# STM32F410Rx register map
File version: 1.0
Registers are 32-bit, read-write, reset 0x0 unless marked. A register's access mark holds for its fields unless they carry their own. Offsets are from the block's base; [hi:lo] are bit positions.

## FMPI2C1 — Inter-integrated Circuit Interface
Base 0x40006000
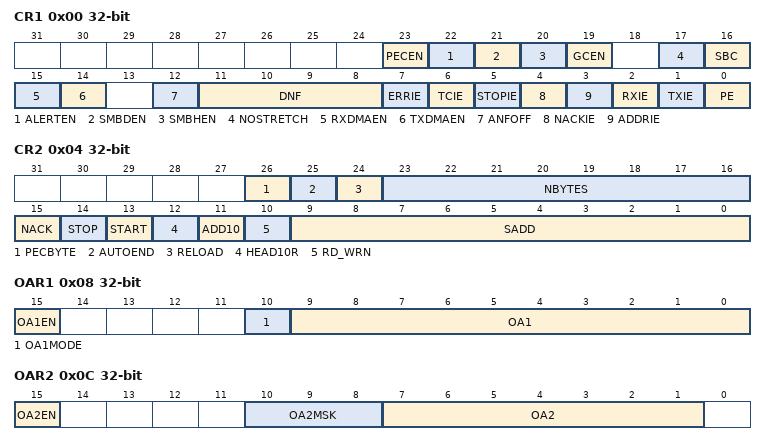
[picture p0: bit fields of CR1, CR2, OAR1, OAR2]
0x00 CR1 — FMPI2C Control register 1
  [23] PECEN — PEC enable
  [22] ALERTEN — SMBus alert enable
  [21] SMBDEN — SMBus device default address enable
  [20] SMBHEN — SMBus host address enable
  [19] GCEN — General call enable
  [17] NOSTRETCH — Clock stretching disable
  [16] SBC — Slave byte control
  [15] RXDMAEN — DMA reception requests enable
  [14] TXDMAEN — DMA transmission requests enable
  [12] ANFOFF — Analog noise filter OFF
  [11:8] DNF — Digital noise filter
  [7] ERRIE — Errors interrupt enable
  [6] TCIE — Transfer complete interrupt enable
  [5] STOPIE — STOP detection interrupt enable
  [4] NACKIE — NACK received interrupt enable
  [3] ADDRIE — Address match interrupt enable
  [2] RXIE — RX interrupt enable
  [1] TXIE — TX interrupt enable
  [0] PE — Peripheral enable
0x04 CR2 — FMPI2C Control register 2
  [26] PECBYTE — Packet error checking byte
  [25] AUTOEND — Automatic end mode (master mode)
  [24] RELOAD — NBYTES reload mode
  [23:16] NBYTES — Number of bytes
  [15] NACK — NACK generation (slave mode)
  [14] STOP — STOP generation (master mode)
  [13] START — START generation
  [12] HEAD10R — 10-bit address header only read direction (master mode)
  [11] ADD10 — 10-bit addressing mode (master mode)
  [10] RD_WRN — Transfer direction (master mode)
  [9:0] SADD — Slave address (master mode)
0x08 OAR1 — FMPI2C Own address 1 register
  [15] OA1EN — Own address 1 enable
  [10] OA1MODE — Own address 1 10-bit mode
  [9:0] OA1 — Interface own address 1
0x0C OAR2 — FMPI2C Own address 2 register
  [15] OA2EN — Own address 2 enable
  [10:8] OA2MSK — Own address 2 masks
  [7:1] OA2 — Interface own address 2
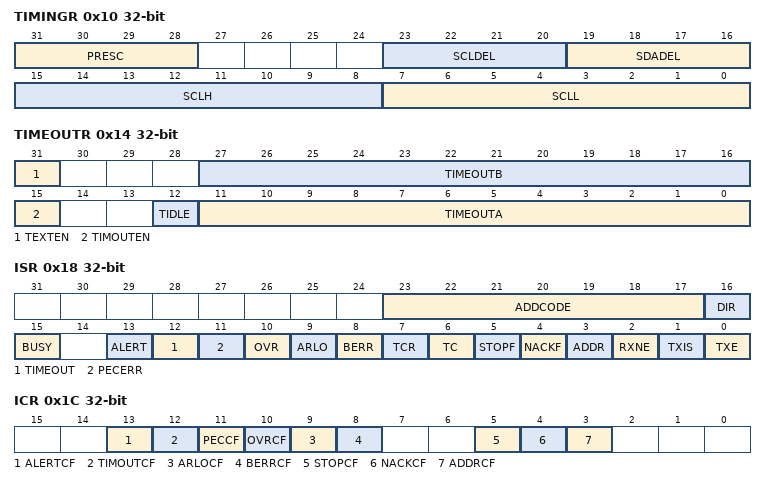
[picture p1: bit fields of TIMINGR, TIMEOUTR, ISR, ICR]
0x10 TIMINGR — FMPI2C Timing register
  [31:28] PRESC — Timings prescaler
  [23:20] SCLDEL — Data setup time
  [19:16] SDADEL — Data hold time
  [15:8] SCLH — SCL high period (master mode)
  [7:0] SCLL — SCL low period (master mode)
0x14 TIMEOUTR — FMPI2C Timeout register
  [31] TEXTEN — Extended clock timeout enable
  [27:16] TIMEOUTB — Bus timeout B
  [15] TIMOUTEN — Clock timeout enable
  [12] TIDLE — Idle clock timeout detection
  [11:0] TIMEOUTA — Bus timeout A
0x18 ISR — FMPI2C Interrupt and status register
  [23:17] ADDCODE — Address match code (slave mode)
  [16] DIR — Transfer direction (slave mode)
  [15] BUSY — Bus busy
  [13] ALERT — SMBus alert
  [12] TIMEOUT — Timeout or Tlow detection flag
  [11] PECERR — PEC error in reception
  [10] OVR — Overrun/Underrun
  [9] ARLO — Arbitration lost
  [8] BERR — Bus error
  [7] TCR — Transfer complete reload
  [6] TC — Transfer complete (master mode)
  [5] STOPF — STOP detection flag
  [4] NACKF — NACK received flag
  [3] ADDR — Address matched (slave mode)
  [2] RXNE — Receive data register not empty
  [1] TXIS — Transmit interrupt status
  [0] TXE — Transmit data register empty
0x1C ICR — FMPI2C Interrupt clear register
  [13] ALERTCF — Alert clear flag
  [12] TIMOUTCF — Timeout clear flag
  [11] PECCF — PAC error clear flag
  [10] OVRCF — Overrun/Underrun clear flag
  [9] ARLOCF — Arbitration lost clear flag
  [8] BERRCF — Bus error clear flag
  [5] STOPCF — STOP detection clear flag
  [4] NACKCF — NACK clear flag
  [3] ADDRCF — Address matched clear flag
0x20 PECR — FMPI2C PEC register
  [7:0] PEC
0x24 RXDR — FMPI2C Receive data register
  [7:0] RXDATA — 8-bit receive data
0x28 TXDR — FMPI2C Transmit data register
  [7:0] TXDATA — 8-bit transmit data

## PWR — Power Control
Base 0x40007000
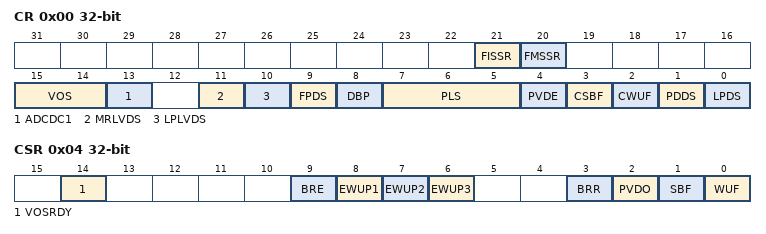
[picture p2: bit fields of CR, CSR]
0x00 CR — PWR power control register
  [21] FISSR — Flash Interface Stop while System Run
  [20] FMSSR — Flash Memory Sleep System Run
  [15:14] VOS — VOS[1:0] bits (Regulator voltage scaling output selection)
    3=SCALE1; 2=SCALE2; 1=SCALE3
  [13] ADCDC1 — Refer to AN4073 on how to use this bit
  [11] MRLVDS — Main Regulator Low Voltage in Deep Sleep mode
  [10] LPLVDS — Low Power Regulator Low Voltage in Deep Sleep mode
  [9] FPDS — Flash power down in Stop mode
  [8] DBP — Disable Backup Domain write protection
  [7:5] PLS — PLS[2:0] bits (PVD Level Selection)
    0=PVDLEVEL_0 (Voltage threshold detected by PVD 2.2 V); 1=PVDLEVEL_1 (Voltage threshold detected by PVD 2.3 V); 2=PVDLEVEL_2 (Voltage threshold detected by PVD 2.4 V); 3=PVDLEVEL_3 (Voltage threshold detected by PVD 2.5 V); 4=PVDLEVEL_4 (Voltage threshold detected by PVD 2.6 V); 5=PVDLEVEL_5 (Voltage threshold detected by PVD 2.7 V); 6=PVDLEVEL_6 (Voltage threshold detected by PVD 2.8 V); 7=PVDLEVEL_7 (Voltage threshold detected by PVD 2.9 V)
  [4] PVDE — Power Voltage Detector Enable
  [3] CSBF — Clear Standby Flag
  [2] CWUF — Clear Wakeup Flag
  [1] PDDS — Power Down Deepsleep
  [0] LPDS — Low-Power Deepsleep
    0=MAIN (Voltage Regulator in main mode during deepsleep mode); 1=LOW_POWER (Voltage Regulator in low-power mode during deepsleep mode)
0x04 CSR — PWR power control/status register
  [14] VOSRDY — Regulator voltage scaling output selection ready
  [9] BRE — Backup regulator enable
  [8] EWUP1 — Enable WKUP pin 1
  [7] EWUP2 — Enable WKUP pin 2
  [6] EWUP3 — Enable WKUP pin 3
  [3] BRR — Backup regulator ready
  [2] PVDO — PVD Output
  [1] SBF — Standby Flag
  [0] WUF — Wakeup Flag
